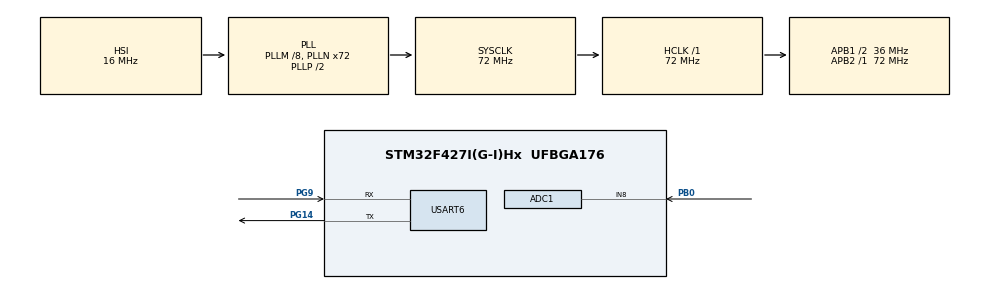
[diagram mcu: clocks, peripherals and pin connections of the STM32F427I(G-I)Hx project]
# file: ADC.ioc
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ADC1.Channel-1\#ChannelRegularConversion=ADC_CHANNEL_8
ADC1.ContinuousConvMode=ENABLE
ADC1.NbrOfConversionFlag=1
ADC1.Rank-1\#ChannelRegularConversion=1
ADC1.SamplingTime-1\#ChannelRegularConversion=ADC_SAMPLETIME_3CYCLES
ADC1.ScanConvMode=ENABLE
ADC1.master=1
Mcu.Family=STM32F4
Mcu.Name=STM32F427I(G-I)Hx
Mcu.Package=UFBGA176
NVIC.PriorityGroup=NVIC_PRIORITYGROUP_4
PA13.Mode=Serial_Wire
PA13.Signal=SYS_JTMS-SWDIO
PA14.Mode=Serial_Wire
PA14.Signal=SYS_JTCK-SWCLK
PB0.Signal=SharedAnalog_PB0
PG14.Mode=Asynchronous
PG14.Signal=USART6_TX
PG9.Mode=Asynchronous
PG9.Signal=USART6_RX
PH0/OSC_IN.Mode=HSE-External-Oscillator
PH0/OSC_IN.Signal=RCC_OSC_IN
PH1/OSC_OUT.Mode=HSE-External-Oscillator
PH1/OSC_OUT.Signal=RCC_OSC_OUT
ProjectManager.HeapSize=0x200
ProjectManager.StackSize=0x400
ProjectManager.TargetToolchain=MDK-ARM V5
RCC.48MHZClocksFreq_Value=36000000
RCC.AHBFreq_Value=72000000
RCC.APB1CLKDivider=RCC_HCLK_DIV2
RCC.APB1Freq_Value=36000000
RCC.APB1TimFreq_Value=72000000
RCC.APB2Freq_Value=72000000
RCC.APB2TimFreq_Value=72000000
RCC.CortexFreq_Value=72000000
RCC.HCLKFreq_Value=72000000
RCC.HSE_VALUE=25000000
RCC.HSI_VALUE=16000000
RCC.LSE_VALUE=32768
RCC.PLLM=8
RCC.PLLN=72
RCC.SYSCLKFreq_VALUE=72000000
RCC.SYSCLKSource=RCC_SYSCLKSOURCE_PLLCLK
RCC.VCOOutputFreq_Value=144000000
SH.SharedAnalog_PB0.0=GPIO_Analog
SH.SharedAnalog_PB0.1=ADC1_IN8,IN8
USART6.VirtualMode=VM_ASYNC
board=custom

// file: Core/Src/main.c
/* USER CODE BEGIN Header */
/**
  ******************************************************************************
  * @file           : main.c
  * @brief          : Main program body
  ******************************************************************************
  * @attention
  *
  * <h2><center>&copy; Copyright (c) 2021 STMicroelectronics.
  * All rights reserved.</center></h2>
  *
  * This software component is licensed by ST under BSD 3-Clause license,
  * the "License"; You may not use this file except in compliance with the
  * License. You may obtain a copy of the License at:
  *                        opensource.org/licenses/BSD-3-Clause
  *
  ******************************************************************************
  */
/* USER CODE END Header */
#include "main.h"
#include <stdio.h>

ADC_HandleTypeDef hadc1;

UART_HandleTypeDef huart6;

void SystemClock_Config(void);
static void MX_GPIO_Init(void);
static void MX_ADC1_Init(void);
static void MX_USART6_UART_Init(void);

/*
#ifdef __GNUC__
#define PUTCHAR_PROTOTYPE int __io_putchar(int ch)
#else
#define PUTCHAR_PROTOTYPE int fputc(int ch, FILE *f)
#endif
PUTCHAR_PROTOTYPE
{
	HAL_UART_Transmit(&huart6, (uint8_t *)&ch, 1, 0xFFFF);
	return ch;
}
*/

uint32_t ADC_Get_Average(uint8_t ch, uint8_t times){

	ADC_ChannelConfTypeDef sConfig; // initialization
	uint32_t value_sum = 0;

	switch(ch) // choose ADC channel
	{
		case 1: sConfig.Channel = ADC_CHANNEL_1; break;
		case 2: sConfig.Channel = ADC_CHANNEL_2; break;
		case 3: sConfig.Channel = ADC_CHANNEL_3; break;
		case 4: sConfig.Channel = ADC_CHANNEL_4; break;
		case 5: sConfig.Channel = ADC_CHANNEL_5; break;
		case 6: sConfig.Channel = ADC_CHANNEL_6; break;
		case 7: sConfig.Channel = ADC_CHANNEL_7; break;
		case 8: sConfig.Channel = ADC_CHANNEL_8; break;
		case 9: sConfig.Channel = ADC_CHANNEL_9; break;
		case 10: sConfig.Channel = ADC_CHANNEL_10; break;
		case 11: sConfig.Channel = ADC_CHANNEL_11; break;
		case 12: sConfig.Channel = ADC_CHANNEL_12; break;
		case 13: sConfig.Channel = ADC_CHANNEL_13; break;
		case 14: sConfig.Channel = ADC_CHANNEL_14; break;
		case 15: sConfig.Channel = ADC_CHANNEL_15; break;
		case 16: sConfig.Channel = ADC_CHANNEL_16; break;
		case 17: sConfig.Channel = ADC_CHANNEL_17; break;
		case 18: sConfig.Channel = ADC_CHANNEL_18; break;
	}

	sConfig.SamplingTime = ADC_SAMPLETIME_144CYCLES; // 144 cycles
	sConfig.Rank = 1;
	HAL_ADC_ConfigChannel(&hadc1, &sConfig);
	for(uint8_t i=0; i<times; ++i){
		HAL_ADC_Start(&hadc1); // start conversion
		HAL_ADC_PollForConversion(&hadc1,30); // wait for finishing conversion
		value_sum += HAL_ADC_GetValue(&hadc1); // sum
		HAL_ADC_Stop(&hadc1); // stop conversion
	}
	return value_sum/times;
}

int main(void)
{

  /* MCU Configuration--------------------------------------------------------*/

  /* Reset of all peripherals, Initializes the Flash interface and the Systick. */
  HAL_Init();

  /* Configure the system clock */
  SystemClock_Config();

  /* Initialize all configured peripherals */
  MX_GPIO_Init();
  MX_ADC1_Init();
  MX_USART6_UART_Init();
  /* USER CODE BEGIN 2 */
	uint16_t voltage_get = 0;
	uint8_t voltage_high;
	uint8_t voltage_low;
	uint8_t voltage_merge[2];
//	HAL_ADCEx_Calibration_Start(&hadc1); // calibration
  /* USER CODE END 2 */

  /* Infinite loop */
  /* USER CODE BEGIN WHILE */
  while (1)
  {
		HAL_Delay(500);
		voltage_get = ADC_Get_Average(8,1);
		//printf("Voltage:%d", 0);
		//uint16_t voltage_get = 12337;
		voltage_high = (uint8_t)(voltage_get >> 8);
		voltage_low = (uint8_t)(voltage_get & 0x00FF);
		voltage_merge[0] = voltage_high;
		voltage_merge[1] = voltage_low;
		HAL_UART_Transmit(&huart6, &voltage_merge[0], 2, 0xFFFF);
		uint8_t data = '\n';
		HAL_UART_Transmit(&huart6, &data, 1, 0xFFFF);
    //printf("\n\r UART \n\r");
		/* USER CODE END WHILE */

  }
}

void SystemClock_Config(void)
{
  RCC_OscInitTypeDef RCC_OscInitStruct = {0};
  RCC_ClkInitTypeDef RCC_ClkInitStruct = {0};

  /** Configure the main internal regulator output voltage
  */
  __HAL_RCC_PWR_CLK_ENABLE();
  __HAL_PWR_VOLTAGESCALING_CONFIG(PWR_REGULATOR_VOLTAGE_SCALE3);
  /** Initializes the RCC Oscillators according to the specified parameters
  * in the RCC_OscInitTypeDef structure.
  */
  RCC_OscInitStruct.OscillatorType = RCC_OSCILLATORTYPE_HSI;
  RCC_OscInitStruct.HSIState = RCC_HSI_ON;
  RCC_OscInitStruct.HSICalibrationValue = RCC_HSICALIBRATION_DEFAULT;
  RCC_OscInitStruct.PLL.PLLState = RCC_PLL_ON;
  RCC_OscInitStruct.PLL.PLLSource = RCC_PLLSOURCE_HSI;
  RCC_OscInitStruct.PLL.PLLM = 8;
  RCC_OscInitStruct.PLL.PLLN = 72;
  RCC_OscInitStruct.PLL.PLLP = RCC_PLLP_DIV2;
  RCC_OscInitStruct.PLL.PLLQ = 4;
  if (HAL_RCC_OscConfig(&RCC_OscInitStruct) != HAL_OK)
  {
    Error_Handler();
  }
  /** Initializes the CPU, AHB and APB buses clocks
  */
  RCC_ClkInitStruct.ClockType = RCC_CLOCKTYPE_HCLK|RCC_CLOCKTYPE_SYSCLK
                              |RCC_CLOCKTYPE_PCLK1|RCC_CLOCKTYPE_PCLK2;
  RCC_ClkInitStruct.SYSCLKSource = RCC_SYSCLKSOURCE_PLLCLK;
  RCC_ClkInitStruct.AHBCLKDivider = RCC_SYSCLK_DIV1;
  RCC_ClkInitStruct.APB1CLKDivider = RCC_HCLK_DIV2;
  RCC_ClkInitStruct.APB2CLKDivider = RCC_HCLK_DIV1;

  if (HAL_RCC_ClockConfig(&RCC_ClkInitStruct, FLASH_LATENCY_2) != HAL_OK)
  {
    Error_Handler();
  }
}

static void MX_ADC1_Init(void)
{

  ADC_ChannelConfTypeDef sConfig = {0};

  /** Configure the global features of the ADC (Clock, Resolution, Data Alignment and number of conversion)
  */
  hadc1.Instance = ADC1;
  hadc1.Init.ClockPrescaler = ADC_CLOCK_SYNC_PCLK_DIV2;
  hadc1.Init.Resolution = ADC_RESOLUTION_12B;
  hadc1.Init.ScanConvMode = ENABLE;
  hadc1.Init.ContinuousConvMode = ENABLE;
  hadc1.Init.DiscontinuousConvMode = DISABLE;
  hadc1.Init.ExternalTrigConvEdge = ADC_EXTERNALTRIGCONVEDGE_NONE;
  hadc1.Init.ExternalTrigConv = ADC_SOFTWARE_START;
  hadc1.Init.DataAlign = ADC_DATAALIGN_RIGHT;
  hadc1.Init.NbrOfConversion = 1;
  hadc1.Init.DMAContinuousRequests = DISABLE;
  hadc1.Init.EOCSelection = ADC_EOC_SINGLE_CONV;
  if (HAL_ADC_Init(&hadc1) != HAL_OK)
  {
    Error_Handler();
  }
  /** Configure for the selected ADC regular channel its corresponding rank in the sequencer and its sample time.
  */
  sConfig.Channel = ADC_CHANNEL_8;
  sConfig.Rank = 1;
  sConfig.SamplingTime = ADC_SAMPLETIME_3CYCLES;
  if (HAL_ADC_ConfigChannel(&hadc1, &sConfig) != HAL_OK)
  {
    Error_Handler();
  }

}

static void MX_USART6_UART_Init(void)
{

  huart6.Instance = USART6;
  huart6.Init.BaudRate = 115200;
  huart6.Init.WordLength = UART_WORDLENGTH_8B;
  huart6.Init.StopBits = UART_STOPBITS_1;
  huart6.Init.Parity = UART_PARITY_NONE;
  huart6.Init.Mode = UART_MODE_TX_RX;
  huart6.Init.HwFlowCtl = UART_HWCONTROL_NONE;
  huart6.Init.OverSampling = UART_OVERSAMPLING_16;
  if (HAL_UART_Init(&huart6) != HAL_OK)
  {
    Error_Handler();
  }

}

static void MX_GPIO_Init(void)
{

  /* GPIO Ports Clock Enable */
  __HAL_RCC_GPIOG_CLK_ENABLE();
  __HAL_RCC_GPIOA_CLK_ENABLE();
  __HAL_RCC_GPIOH_CLK_ENABLE();
  __HAL_RCC_GPIOB_CLK_ENABLE();

}

void Error_Handler(void)
{
  __disable_irq();
  while (1)
  {
  }
}

/************************ (C) COPYRIGHT STMicroelectronics *****END OF FILE****/
